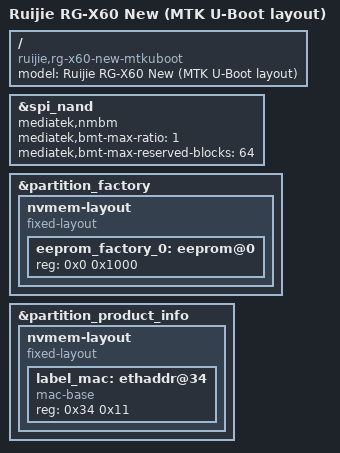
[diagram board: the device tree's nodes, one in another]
// SPDX-License-Identifier: (GPL-2.0 OR MIT)

/dts-v1/;
#include "mt7986a-ruijie-rg-x60-new-common.dtsi"

/ {
	model = "Ruijie RG-X60 New (MTK U-Boot layout)";
	compatible = "ruijie,rg-x60-new-mtkuboot", "mediatek,mt7986a";
};

&spi_nand {
	mediatek,nmbm;
	mediatek,bmt-max-ratio = <1>;
	mediatek,bmt-max-reserved-blocks = <64>;
};

&partition_factory {
	nvmem-layout {
		compatible = "fixed-layout";
		#address-cells = <1>;
		#size-cells = <1>;

		eeprom_factory_0: eeprom@0 {
			reg = <0x0 0x1000>;
		};
	};
};

&partition_product_info {
	nvmem-layout {
		compatible = "fixed-layout";
		#address-cells = <1>;
		#size-cells = <1>;

		label_mac: ethaddr@34 {
			compatible = "mac-base";
			reg = <0x34 0x11>;
			#nvmem-cell-cells = <1>;
		};
	};
};
